# STM32F429 register map
File version: 1.2
CPU: CM4 r1p0, little endian, no MPU, no FPU, 3 interrupt priority bits
Registers are 32-bit, read-write, reset 0x0 unless marked. A register's access mark holds for its fields unless they carry their own. Offsets are from the block's base; [hi:lo] are bit positions.

## PWR — Power control
Base 0x40007000
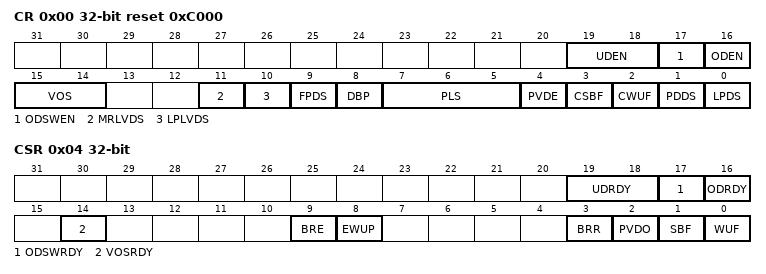
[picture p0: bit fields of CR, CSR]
0x00 CR reset 0xC000 — power control register
  [19:18] UDEN — Under-drive enable in stop mode
  [17] ODSWEN — Over-drive switching enabled
  [16] ODEN — Over-drive enable
  [15:14] VOS — Regulator voltage scaling output selection
  [11] MRLVDS — Main regulator low voltage in deepsleep mode
  [10] LPLVDS — Low-Power Regulator Low Voltage in deepsleep
  [9] FPDS — Flash power down in Stop mode
  [8] DBP — Disable backup domain write protection
  [7:5] PLS — PVD level selection
  [4] PVDE — Power voltage detector enable
  [3] CSBF — Clear standby flag
  [2] CWUF — Clear wakeup flag
  [1] PDDS — Power down deepsleep
  [0] LPDS — Low-power deep sleep
0x04 CSR access per field — power control/status register
  [19:18] UDRDY rw — Under-drive ready flag
  [17] ODSWRDY ro — Over-drive mode switching ready
  [16] ODRDY ro — Over-drive mode ready
  [14] VOSRDY rw — Regulator voltage scaling output selection ready bit
  [9] BRE rw — Backup regulator enable
  [8] EWUP rw — Enable WKUP pin
  [3] BRR ro — Backup regulator ready
  [2] PVDO ro — PVD output
  [1] SBF ro — Standby flag
  [0] WUF ro — Wakeup flag

## IWDG — Independent watchdog
Base 0x40003000
0x00 KR wo — Key register
  [15:0] KEY — Key value (write only, read 0000h)
0x04 PR — Prescaler register
  [2:0] PR — Prescaler divider
0x08 RLR reset 0xFFF — Reload register
  [11:0] RL — Watchdog counter reload value
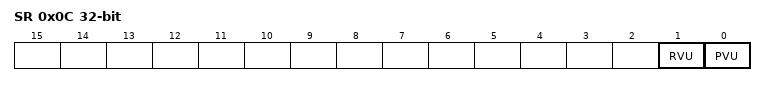
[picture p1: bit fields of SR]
0x0C SR ro — Status register
  [1] RVU — Watchdog counter reload value update
  [0] PVU — Watchdog prescaler value update

## WWDG — Window watchdog
Base 0x40002C00
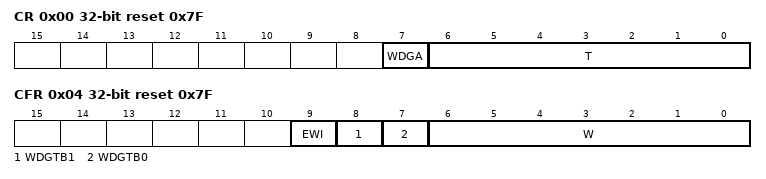
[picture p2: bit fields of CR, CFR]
0x00 CR reset 0x7F — Control register
  [7] WDGA — Activation bit
  [6:0] T — 7-bit counter (MSB to LSB)
0x04 CFR reset 0x7F — Configuration register
  [9] EWI — Early wakeup interrupt
  [8] WDGTB1 — Timer base
  [7] WDGTB0 — Timer base
  [6:0] W — 7-bit window value
0x08 SR — Status register
  [0] EWIF — Early wakeup interrupt flag

## UART4 — Universal synchronous asynchronous receiver transmitter
Base 0x40004C00
Same registers: UART5 0x40005000
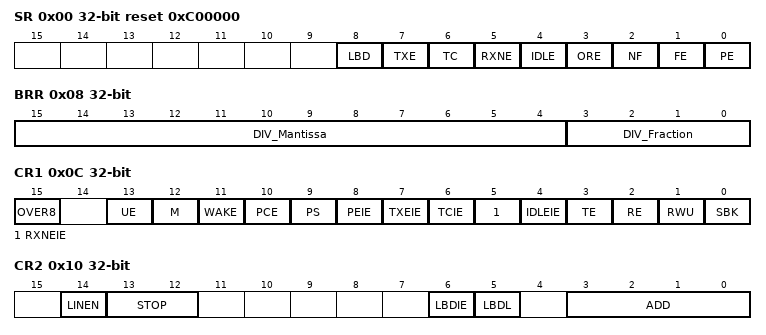
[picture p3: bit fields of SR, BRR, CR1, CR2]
0x00 SR access per field reset 0xC00000 — Status register
  [8] LBD rw — LIN break detection flag
  [7] TXE ro — Transmit data register empty
  [6] TC rw — Transmission complete
  [5] RXNE rw — Read data register not empty
  [4] IDLE ro — IDLE line detected
  [3] ORE ro — Overrun error
  [2] NF ro — Noise detected flag
  [1] FE ro — Framing error
  [0] PE ro — Parity error
0x04 DR — Data register
  [8:0] DR — Data value
0x08 BRR — Baud rate register
  [15:4] DIV_Mantissa — mantissa of USARTDIV
  [3:0] DIV_Fraction — fraction of USARTDIV
0x0C CR1 — Control register 1
  [15] OVER8 — Oversampling mode
  [13] UE — USART enable
  [12] M — Word length
  [11] WAKE — Wakeup method
  [10] PCE — Parity control enable
  [9] PS — Parity selection
  [8] PEIE — PE interrupt enable
  [7] TXEIE — TXE interrupt enable
  [6] TCIE — Transmission complete interrupt enable
  [5] RXNEIE — RXNE interrupt enable
  [4] IDLEIE — IDLE interrupt enable
  [3] TE — Transmitter enable
  [2] RE — Receiver enable
  [1] RWU — Receiver wakeup
  [0] SBK — Send break
0x10 CR2 — Control register 2
  [14] LINEN — LIN mode enable
  [13:12] STOP — STOP bits
  [6] LBDIE — LIN break detection interrupt enable
  [5] LBDL — lin break detection length
  [3:0] ADD — Address of the USART node
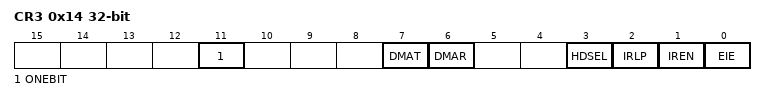
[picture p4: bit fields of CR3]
0x14 CR3 — Control register 3
  [11] ONEBIT — One sample bit method enable
  [7] DMAT — DMA enable transmitter
  [6] DMAR — DMA enable receiver
  [3] HDSEL — Half-duplex selection
  [2] IRLP — IrDA low-power
  [1] IREN — IrDA mode enable
  [0] EIE — Error interrupt enable

## C_ADC — Common ADC registers
Base 0x40012300
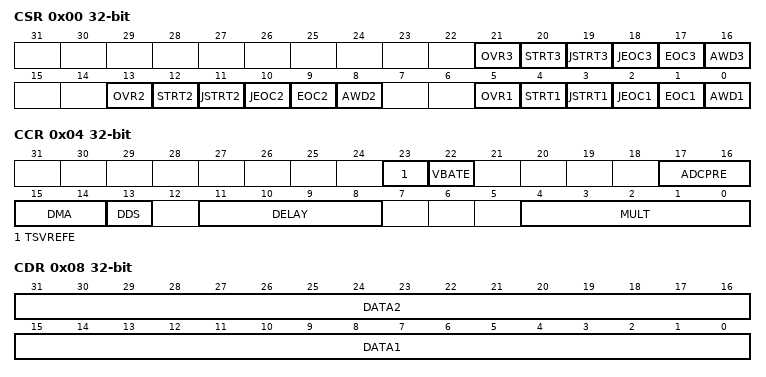
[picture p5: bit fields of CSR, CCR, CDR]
0x00 CSR ro — ADC Common status register
  [21] OVR3 — Overrun flag of ADC3
  [20] STRT3 — Regular channel Start flag of ADC 3
  [19] JSTRT3 — Injected channel Start flag of ADC 3
  [18] JEOC3 — Injected channel end of conversion of ADC 3
  [17] EOC3 — End of conversion of ADC 3
  [16] AWD3 — Analog watchdog flag of ADC 3
  [13] OVR2 — Overrun flag of ADC 2
  [12] STRT2 — Regular channel Start flag of ADC 2
  [11] JSTRT2 — Injected channel Start flag of ADC 2
  [10] JEOC2 — Injected channel end of conversion of ADC 2
  [9] EOC2 — End of conversion of ADC 2
  [8] AWD2 — Analog watchdog flag of ADC 2
  [5] OVR1 — Overrun flag of ADC 1
  [4] STRT1 — Regular channel Start flag of ADC 1
  [3] JSTRT1 — Injected channel Start flag of ADC 1
  [2] JEOC1 — Injected channel end of conversion of ADC 1
  [1] EOC1 — End of conversion of ADC 1
  [0] AWD1 — Analog watchdog flag of ADC 1
0x04 CCR — ADC common control register
  [23] TSVREFE — Temperature sensor and VREFINT enable
  [22] VBATE — VBAT enable
  [17:16] ADCPRE — ADC prescaler
  [15:14] DMA — Direct memory access mode for multi ADC mode
  [13] DDS — DMA disable selection for multi-ADC mode
  [11:8] DELAY — Delay between 2 sampling phases
  [4:0] MULT — Multi ADC mode selection
0x08 CDR ro — ADC common regular data register for dual and triple modes
  [31:16] DATA2 — 2nd data item of a pair of regular conversions
  [15:0] DATA1 — 1st data item of a pair of regular conversions
